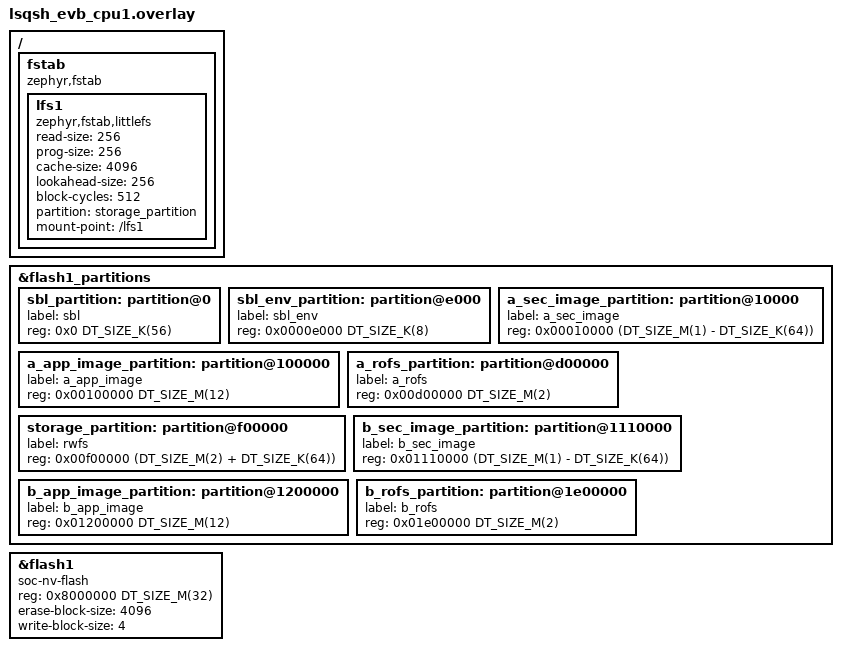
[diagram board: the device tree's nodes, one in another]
/*
 * Copyright (c) 2023 Nordic Semiconductor ASA
 *
 * SPDX-License-Identifier: Apache-2.0
 */

/* Because FAT FS needs at least 64kiB partition and default
 * storage_partition is 32kiB for that board, we need to reorgatnize
 * partitions to get at least 64KiB.
 * This overlay removes image slot partitions and strips each of 64kiB,
 * and removes the storage partition to add the additional 2*64kiB to
 * it.
 */

&flash1_partitions {
    /* sbl */
    sbl_partition: partition@0 {
        label = "sbl";
        reg = <0x0 DT_SIZE_K(56)>;
    };
    sbl_env_partition: partition@e000 {
        label = "sbl_env";
        reg = <0x0000e000 DT_SIZE_K(8)>;
    };

    /* a */
    a_sec_image_partition: partition@10000 {
        label = "a_sec_image";
        reg = <0x00010000 (DT_SIZE_M(1) - DT_SIZE_K(64))>;
    };
    a_app_image_partition: partition@100000 {
        label = "a_app_image";
        reg = <0x00100000 DT_SIZE_M(12)>;
    };
    a_rofs_partition: partition@d00000 {
        label = "a_rofs";
        reg = <0x00d00000 DT_SIZE_M(2)>;
    };

    /* common *//*rwfs_partition*/
    storage_partition: partition@f00000 {
        label = "rwfs";
        reg = <0x00f00000 (DT_SIZE_M(2) + DT_SIZE_K(64))>;
    };

    /* b */
    b_sec_image_partition: partition@1110000 {
        label = "b_sec_image";
        reg = <0x01110000 (DT_SIZE_M(1) - DT_SIZE_K(64))>;
    };
    b_app_image_partition: partition@1200000 {
        label = "b_app_image";
        reg = <0x01200000 DT_SIZE_M(12)>;
    };
    b_rofs_partition: partition@1e00000 {
        label = "b_rofs";
        reg = <0x01e00000 DT_SIZE_M(2)>;
    };
};

&flash1 {
    compatible = "soc-nv-flash";
    reg = <0x8000000 DT_SIZE_M(32)>;
    erase-block-size = <4096>;
    write-block-size = <4>;
};

/ {
	fstab {
		compatible = "zephyr,fstab";
		lfs1: lfs1 {
			compatible = "zephyr,fstab,littlefs";
			read-size = <256>;
			prog-size = <256>;
			cache-size = <4096>;
			lookahead-size = <256>;
			block-cycles = <512>;
			partition = <&storage_partition>;
			mount-point = "/lfs1";
		};
	};
};
